VERSION "Excel 2 DBC"

NS_ :

BS_:

BU_: Gateway DOOR_ri DOOR_le Dashboard Console
VAL_TABLE_ Active 0 "None" 1 "Turn_right" 2 "Turn_left" 3 "Warning";
VAL_TABLE_ Gear 0 "Idle" 1 "Gear_1" 2 "Gear_2" 3 "Gear_3" 4 "Gear_4" 5 "Gear_5";

BO_ 1541 TP_Dashboard: 6 Dashboard
 SG_ data : 0|48@1+ (1,0) [0|0] "" Console

BO_ 1053 NM_Gateway: 4 Gateway
 SG_ SleepInd : 12|1@1+ (1,0) [0|0] "" Gateway

BO_ 497 DOOR_r: 1 DOOR_ri
 SG_ WN_Position : 0|8@1+ (1,0) [0|100] "" Vector__XXX

BO_ 496 DOOR_l: 1 DOOR_le
 SG_ WN_Position : 0|8@1+ (1,0) [0|100] "" Vector__XXX

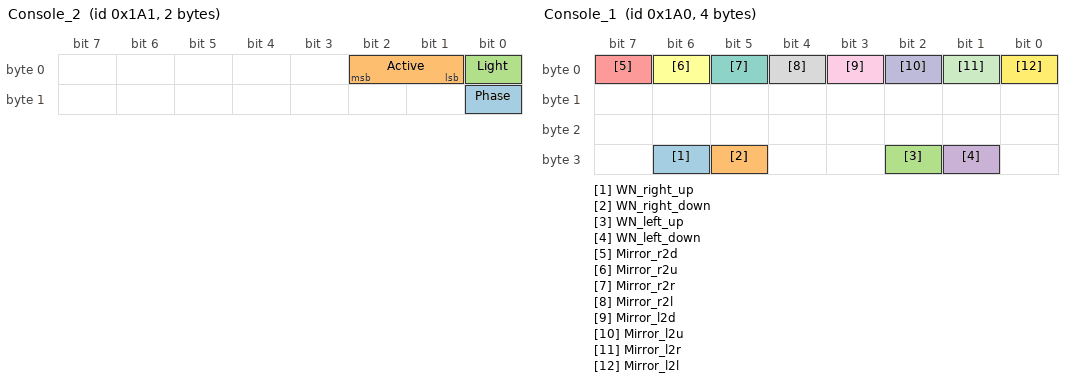
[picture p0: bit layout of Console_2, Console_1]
BO_ 417 Console_2: 2 Console
 SG_ Phase : 8|1@1+ (1,0) [0|0] "" Vector__XXX
 SG_ Active : 1|2@1+ (1,0) [0|0] "" Vector__XXX
 SG_ Light : 0|1@1+ (1,0) [0|1] "" Vector__XXX

BO_ 416 Console_1: 4 Console
 SG_ WN_right_up : 30|1@1+ (1,0) [0|0] "" DOOR_ri
 SG_ WN_right_down : 29|1@1+ (1,0) [0|0] "" DOOR_ri
 SG_ WN_left_up : 26|1@1+ (1,0) [0|0] "" DOOR_le
 SG_ WN_left_down : 25|1@1+ (1,0) [0|0] "" DOOR_le
 SG_ Mirror_r2d : 7|1@1+ (1,0) [0|0] "" Vector__XXX
 SG_ Mirror_r2u : 6|1@1+ (1,0) [0|0] "" Vector__XXX
 SG_ Mirror_r2r : 5|1@1+ (1,0) [0|0] "" Vector__XXX
 SG_ Mirror_r2l : 4|1@1+ (1,0) [0|0] "" Vector__XXX
 SG_ Mirror_l2d : 3|1@1+ (1,0) [0|0] "" Vector__XXX
 SG_ Mirror_l2u : 2|1@1+ (1,0) [0|0] "" Vector__XXX
 SG_ Mirror_l2r : 1|1@1+ (1,0) [0|0] "" Vector__XXX
 SG_ Mirror_l2l : 0|1@1+ (1,0) [0|0] "" Vector__XXX

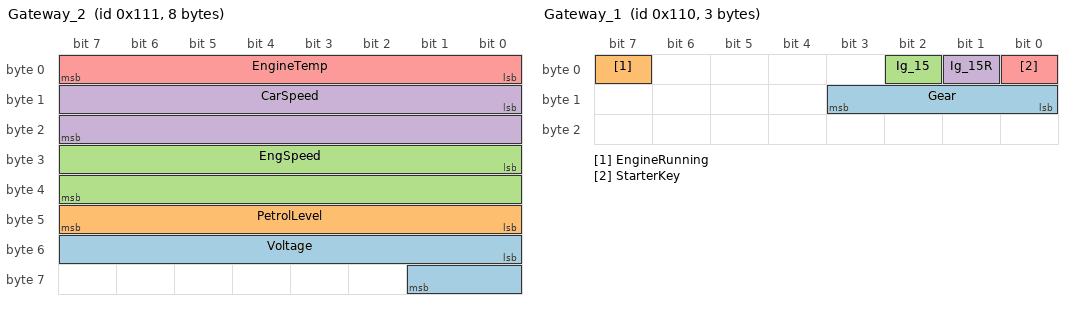
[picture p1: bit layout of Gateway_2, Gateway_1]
BO_ 273 Gateway_2: 8 Gateway
 SG_ Voltage : 48|10@1+ (0.1,0) [0|102.3] "V" Vector__XXX
 SG_ PetrolLevel : 40|8@1+ (1,0) [0|0] "l" Dashboard
 SG_ EngSpeed : 24|16@1+ (1,0) [0|0] "rpm" Dashboard
 SG_ CarSpeed : 8|16@1+ (0.5,0) [0|300] "mph" Dashboard
 SG_ EngineTemp : 0|8@1+ (1,0) [0|0] "degC" Dashboard

BO_ 272 Gateway_1: 3 Gateway
 SG_ Gear : 8|4@1- (1,0) [0|0] "" Dashboard
 SG_ EngineRunning : 7|1@1+ (1,0) [0|0] "" Vector__XXX
 SG_ Ig_15 : 2|1@1+ (1,0) [0|0] "" Dashboard
 SG_ Ig_15R : 1|1@1+ (1,0) [0|0] "" Dashboard
 SG_ StarterKey : 0|1@1+ (1,0) [0|1] "" Dashboard

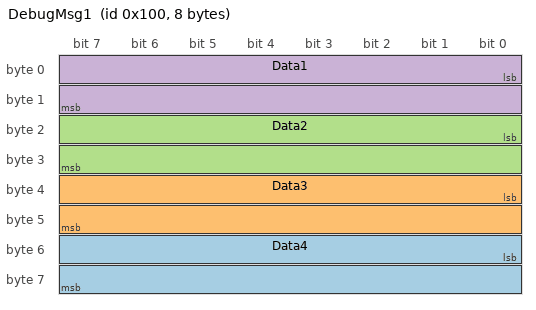
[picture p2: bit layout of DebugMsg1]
BO_ 256 DebugMsg1: 8 Vector__XXX
 SG_ Data4 : 48|16@1- (1,0) [0|0] "" Gateway
 SG_ Data3 : 32|16@1- (1,0) [0|0] "" Gateway
 SG_ Data2 : 16|16@1- (1,0) [0|0] "" Gateway
 SG_ Data1 : 0|16@1- (1,0) [0|0] "" Gateway

BA_DEF_ BO_ "GenMsgCycleTime" INT 0 65535;
BA_ "GenMsgCycleTime" BO_ 497 100;
BA_ "GenMsgCycleTime" BO_ 496 100;
BA_ "GenMsgCycleTime" BO_ 417 50;
BA_ "GenMsgCycleTime" BO_ 416 50;
BA_ "GenMsgCycleTime" BO_ 273 100;
BA_ "GenMsgCycleTime" BO_ 272 20;
VAL_ 417 Active 0 "None" 1 "Turn_right" 2 "Turn_left" 3 "Warning";
VAL_ 272 Gear 0 "Idle" 1 "Gear_1" 2 "Gear_2" 3 "Gear_3" 4 "Gear_4" 5 "Gear_5";
